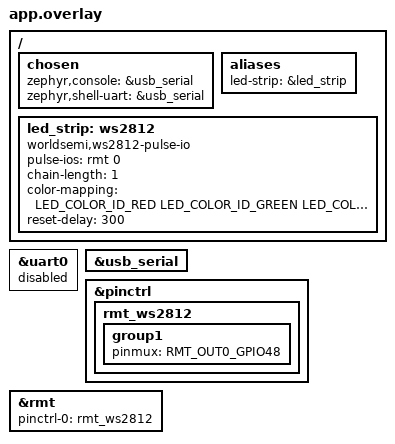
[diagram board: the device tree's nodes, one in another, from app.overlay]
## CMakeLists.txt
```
cmake_minimum_required(VERSION 3.20.0)

find_package(Zephyr REQUIRED HINTS $ENV{ZEPHYR_BASE})
project(blink_test)

target_sources(app PRIVATE src/main.c)
```

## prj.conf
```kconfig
CONFIG_GPIO=y
CONFIG_PRINTK=y
CONFIG_MAIN_STACK_SIZE=2048

CONFIG_LED_STRIP=y
CONFIG_WS2812_STRIP_PULSE_IO=y
```

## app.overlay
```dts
#include <zephyr/dt-bindings/led/led.h>
#include <espressif/esp32s3/esp32s3_wroom_n16.dtsi>

&uart0 {
    status = "disabled";
};

&usb_serial {
    status = "okay";
};

/ {
    chosen {
        zephyr,console = &usb_serial;
        zephyr,shell-uart = &usb_serial;
    };

    aliases {
        led-strip = &led_strip;
    };

    led_strip: ws2812 {
        compatible = "worldsemi,ws2812-pulse-io";
        pulse-ios = <&rmt 0>;
        chain-length = <1>;
        color-mapping = <LED_COLOR_ID_RED
                         LED_COLOR_ID_GREEN
                         LED_COLOR_ID_BLUE>;
        reset-delay = <300>;
    };
};

&pinctrl {
    rmt_ws2812: rmt_ws2812 {
        group1 {
            pinmux = <RMT_OUT0_GPIO48>;
        };
    };
};

&rmt {
    pinctrl-0 = <&rmt_ws2812>;
    pinctrl-names = "default";
    status = "okay";
};
```

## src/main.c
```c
#include <zephyr/device.h>
#include <zephyr/devicetree.h>
#include <zephyr/drivers/led_strip.h>
#include <zephyr/kernel.h>
#include <zephyr/sys/printk.h>

#define STRIP_NODE DT_ALIAS(led_strip)
#define STRIP_LENGTH DT_PROP(STRIP_NODE, chain_length)

static const struct device *const strip = DEVICE_DT_GET(STRIP_NODE);

int main(void)
{
    struct led_rgb pixel[STRIP_LENGTH] = {0};

    if (!device_is_ready(strip)) {
        printk("ERRO: LED RGB nao esta pronto.\n");
        return 0;
    }

    printk("Teste de LED RGB - ESP32-S3\n");

    while (1) {
        pixel[0] = (struct led_rgb){ .r = 255, .g = 0, .b = 0 };
        if (led_strip_update_rgb(strip, pixel, STRIP_LENGTH) < 0) {
            printk("Erro ao acender vermelho.\n");
            return 0;
        }
        printk("Vermelho\n");
        k_msleep(1000);

        pixel[0] = (struct led_rgb){ .r = 0, .g = 255, .b = 0 };
        if (led_strip_update_rgb(strip, pixel, STRIP_LENGTH) < 0) {
            printk("Erro ao acender verde.\n");
            return 0;
        }
        printk("Verde\n");
        k_msleep(1000);

        pixel[0] = (struct led_rgb){ .r = 0, .g = 0, .b = 255 };
        if (led_strip_update_rgb(strip, pixel, STRIP_LENGTH) < 0) {
            printk("Erro ao acender azul.\n");
            return 0;
        }
        printk("Azul\n");
        k_msleep(1000);

        pixel[0] = (struct led_rgb){ .r = 0, .g = 0, .b = 0 };
        if (led_strip_update_rgb(strip, pixel, STRIP_LENGTH) < 0) {
            printk("Erro ao apagar o LED.\n");
            return 0;
        }
        printk("Apagado\n");
        k_msleep(1000);
    }

    return 0;
}
```
